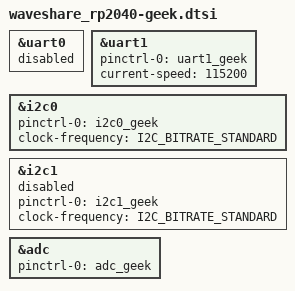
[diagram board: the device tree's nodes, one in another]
/*
 * Copyright (c) 2023-2025 TiaC Systems
 * SPDX-License-Identifier: Apache-2.0
 */

#include <freq.h>
#include <zephyr/dt-bindings/i2c/i2c.h>

#include "waveshare_rp2040.dtsi"

&uart0 {
	status = "disabled";
	/delete-property/ pinctrl-0;
	/delete-property/ pinctrl-names;
	/delete-property/ current-speed;
};

&uart1 {
	status = "okay";
	pinctrl-0 = <&uart1_geek>;
	pinctrl-names = "default";
	current-speed = <115200>;
};

&i2c0 {
	status = "okay";
	pinctrl-0 = <&i2c0_geek>;
	pinctrl-names = "default";
	clock-frequency = <I2C_BITRATE_STANDARD>;
};

&i2c1 {
	status = "disabled";
	pinctrl-0 = <&i2c1_geek>;
	pinctrl-names = "default";
	clock-frequency = <I2C_BITRATE_STANDARD>;
};

&adc {
	status = "okay";
	pinctrl-0 = <&adc_geek>;
	pinctrl-names = "default";
};
